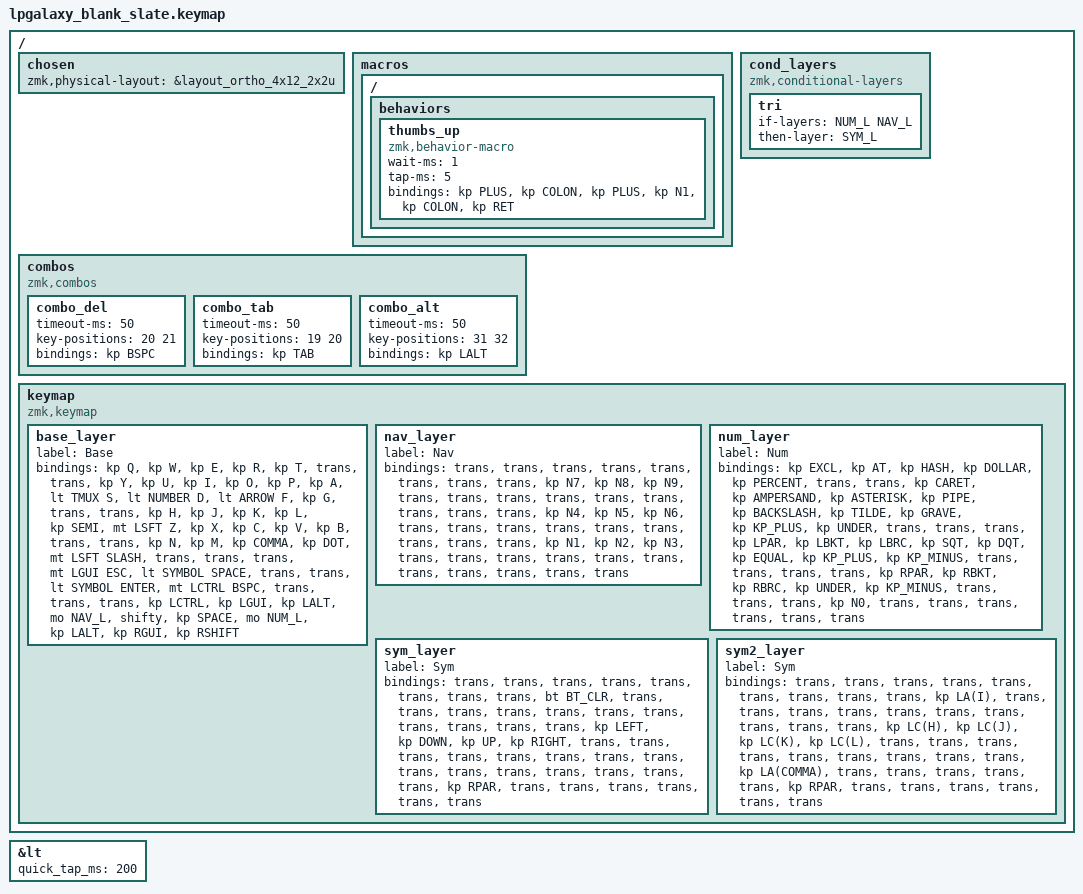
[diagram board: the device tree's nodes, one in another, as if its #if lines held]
/*
 * Copyright (c) 2022 Pete Johanson
 *
 * SPDX-License-Identifier: MIT
 */

#include <behaviors.dtsi>
#include <dt-bindings/zmk/keys.h>
#include <dt-bindings/zmk/bt.h>
#include <dt-bindings/zmk/outputs.h>

#define QWERTY_BASE 1

#define TBLE_ORTHO   1
// #define TBLE_MIT     1
// #define TBLE_DUAL_2U 1

#define NAV_L 1
#define NUM_L 2
#define SYM_L 3


#define BASE 0
#define NUMBER 1
#define SYMBOL 2
#define ARROW 3
#define TMUX 4

// Using layer taps on thumbs, having quick tap as well helps w/ repeating space/backspace
&lt { quick_tap_ms = <200>; };

#define BT(n) BT_SEL n

/ {
    chosen {
       zmk,physical-layout =
#ifdef TBLE_DUAL_2U
                       &layout_ortho_4x12_2x2u;
#elif defined(TBLE_MIT)
                       &layout_ortho_4x12_1x2u;
#else
                       &layout_ortho_4x12_all1u;
#endif
    };

    macros {
      ZMK_MACRO(thumbs_up,
		wait-ms = <1>;
		tap-ms = <5>;
                bindings = <&kp PLUS &kp COLON &kp PLUS &kp N1 &kp COLON &kp RET>;
		)
    };

    combos {
        compatible = "zmk,combos";
        combo_del {
            timeout-ms = <50>;
            key-positions = <20 21>;
            bindings = <&kp BSPC>;
        };
        combo_tab {
            timeout-ms = <50>;
            key-positions = <19 20>;
            bindings = <&kp TAB>;
        };
        
         combo_alt {
            timeout-ms = <50>;
            key-positions = <31 32>;
            bindings = <&kp LALT>;
        };
        
    };
    

// Conditional layer only when we have less thumb keys
#ifdef TBLE_DUAL_2U
    cond_layers {
        compatible = "zmk,conditional-layers";
	tri {
	    if-layers = <NUM_L NAV_L>;
	    then-layer = <SYM_L>;
        };
    };
#endif

    keymap {
        compatible = "zmk,keymap";

        base_layer {
            label = "Base";
            bindings = <
#ifdef QWERTY_BASE
 &kp Q      &kp W      &kp E        &kp R      &kp T      &trans  &trans  &kp Y      &kp U      &kp I      &kp O      &kp P 
 &kp A      &lt TMUX S &lt NUMBER D &lt ARROW F &kp G      &trans  &trans  &kp H      &kp J      &kp K      &kp L      &kp SEMI
 &mt LSFT Z &kp X      &kp C        &kp V      &kp B      &trans  &trans  &kp N      &kp M      &kp COMMA  &kp DOT    &mt LSFT SLASH
#else
 &kp Q      &kp W      &kp E        &kp R      &kp T      &trans  &trans  &kp Y      &kp U      &kp I      &kp O      &kp P 
 &kp A      &lt TMUX S &lt NUMBER D &lt ARROW F &kp G      &trans  &trans  &kp H      &kp J      &kp K      &kp L      &kp SEMI
 &mt LSFT Z &kp X      &kp C        &kp V      &kp B      &trans  &trans  &kp N      &kp M      &kp COMMA  &kp DOT    &mt LSFT SLASH
#endif
#ifdef TBLE_DUAL_2U
 &trans     &trans     &trans       &mt LGUI ESC &lt SYMBOL SPACE &trans  &trans  &lt SYMBOL ENTER &mt LCTRL BSPC &trans     &trans     &trans
 &kp LCTRL  &kp LGUI   &kp LALT   &mo NAV_L         &shifty                        &kp SPACE                &mo NUM_L   &kp LALT   &kp RGUI      &kp RSHIFT
#elif defined(TBLE_MIT)
 &kp LCTRL  &mo SYM_L   &kp LGUI  &kp LALT    &mo NAV_L          &kp SPACE                   &mo NUM_L      &kp LEFT    &kp UP     &kp DOWN      &kp RIGHT
#else
 &trans     &trans     &trans       &mt LGUI ESC &lt SYMBOL SPACE &trans  &trans  &lt SYMBOL ENTER &mt LCTRL BSPC &trans     &trans     &trans
#endif
            >;
        };

        nav_layer {
            label = "Nav";
            bindings = <

 &trans     &trans     &trans     &trans     &trans     &trans  &trans      &trans     &kp N7     &kp N8     &kp N9     &trans
 &trans     &trans     &trans     &trans     &trans     &trans  &trans      &trans     &kp N4     &kp N5     &kp N6     &trans
 &trans     &trans     &trans     &trans     &trans     &trans  &trans      &trans     &kp N1     &kp N2     &kp N3     &trans
#ifdef TBLE_DUAL_2U
&trans  &trans        &trans     &trans              &trans                    &trans       &trans         &trans &trans &trans
#elif defined(TBLE_MIT)
&trans  &trans        &trans     &trans      &trans                &trans             &trans      &trans   &trans &trans &trans
#else
 &trans     &trans     &trans     &trans     &trans     &trans  &trans      &trans     &kp N0     &trans     &trans     &trans
#endif
            >;
        };

        num_layer {
            label = "Num";
            bindings = <

      &kp EXCL      &kp AT         &kp HASH       &kp DOLLAR    &kp PERCENT    &trans     &trans     &kp CARET   &kp AMPERSAND &kp ASTERISK  &kp PIPE     &kp BACKSLASH
      &kp TILDE     &kp GRAVE      &kp KP_PLUS    &kp UNDER     &trans         &trans     &trans     &kp LPAR     &kp LBKT       &kp LBRC      &kp SQT      &kp DQT  
      &kp EQUAL     &kp KP_PLUS    &kp KP_MINUS   &trans         &trans         &trans     &trans     &kp RPAR     &kp RBKT       &kp RBRC      &kp UNDER    &kp KP_MINUS  
#ifdef TBLE_DUAL_2U
&trans  &trans       &trans     &kp N0              &trans                 &trans            &trans         &trans &trans &trans
#elif defined(TBLE_MIT)
&trans  &trans       &trans     &kp N0      &trans           &none            &trans        &kp DEL      &trans &trans &trans
#else
&trans  &trans       &trans     &kp N0      &trans    &none         &none     &kp ESC        &kp DEL      &trans &trans &trans
#endif
            >;
        };

        sym_layer {
            label = "Sym";
            bindings = <
 &trans     &trans     &trans     &trans     &trans     &trans  &trans  &trans     &bt BT_CLR  &trans     &trans     &trans
 &trans     &trans     &trans     &trans     &trans     &trans  &trans  &trans     &kp LEFT  &kp DOWN    &kp UP  &kp RIGHT  
 &trans     &trans     &trans     &trans     &trans     &trans  &trans  &trans     &trans     &trans     &trans     &trans
#ifdef TBLE_DUAL_2U
&trans &trans        &trans     &kp RPAR                &trans                    &trans       &trans         &trans &trans &trans
#elif defined(TBLE_MIT)
&trans &trans        &trans     &kp RPAR        &trans                &trans             &trans      &trans   &trans &trans &trans
#else
 &trans     &trans     &trans     &trans     &trans     &trans  &trans  &trans     &trans     &trans     &trans     &trans
#endif
            >;
        };

        sym2_layer {
            label = "Sym";
            bindings = <

 &trans     &trans     &trans     &trans     &trans     &trans  &trans  &trans     &trans     &kp LA(I)     &trans     &trans
 &trans     &trans     &trans     &trans     &trans     &trans  &trans  &trans   &kp LC(H)    &kp LC(J)      &kp LC(K)    &kp LC(L)
 &trans     &trans     &trans     &trans     &trans     &trans  &trans  &trans     &trans     &kp LA(COMMA)     &trans     &trans
#ifdef TBLE_DUAL_2U
&trans &trans        &trans     &kp RPAR                &trans                    &trans       &trans         &trans &trans &trans
#elif defined(TBLE_MIT)
&trans &trans        &trans     &kp RPAR        &trans                &trans             &trans      &trans   &trans &trans &trans
#else
 &trans     &trans     &trans     &trans     &trans     &trans  &trans  &trans     &trans     &trans           &trans     &trans
#endif
            >;
        };


    };
};

